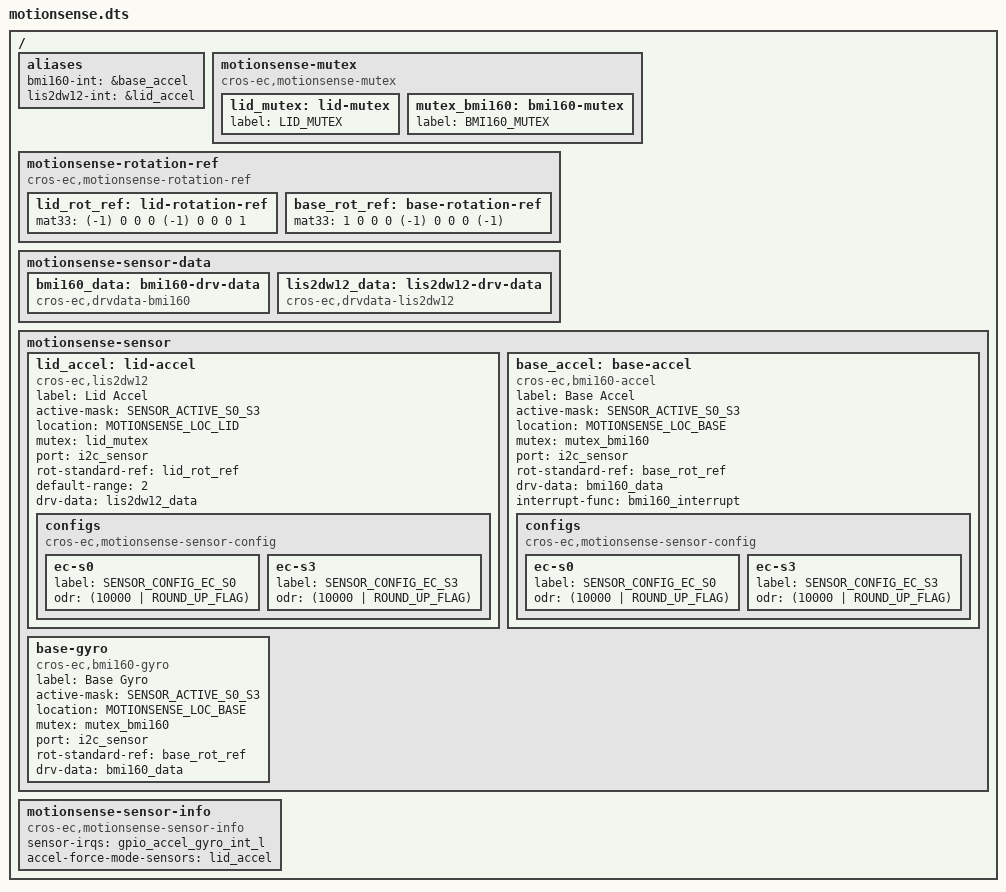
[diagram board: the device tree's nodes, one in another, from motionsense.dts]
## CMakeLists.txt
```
<<<<<<< HEAD   (caf383 driver: add ICM-42607 driver support)
=======
# Copyright 2021 The Chromium OS Authors. All rights reserved.
# Use of this source code is governed by a BSD-style license that can be
# found in the LICENSE file.

cmake_minimum_required(VERSION 3.13.1)
add_compile_definitions(BOARD_HAYATO)

find_package(Zephyr REQUIRED HINTS $ENV{ZEPHYR_BASE})
project(hayato)

zephyr_library_include_directories(include)

set(PLATFORM_EC_BASEBOARD "${PLATFORM_EC}/baseboard/asurada" CACHE PATH
    "Path to the platform/ec baseboard directory")
set(PLATFORM_EC_BOARD "${PLATFORM_EC}/board/hayato" CACHE PATH
  "Path to the platform/ec board directory")

zephyr_library_sources(
  "${PLATFORM_EC_BASEBOARD}/board_chipset.c"
  "${PLATFORM_EC_BASEBOARD}/board_id.c"
  "${PLATFORM_EC_BASEBOARD}/regulator.c"
  "${PLATFORM_EC_BASEBOARD}/usbc_config.c"
  "${PLATFORM_EC_BASEBOARD}/usb_pd_policy.c")

zephyr_library_sources(
  "${PLATFORM_EC_BOARD}/battery.c")

zephyr_library_sources_ifdef(CONFIG_PLATFORM_EC_I2C
  "src/i2c.c")
>>>>>>> CHANGE (2eb53a lid_angle: Create a common callback for lid angle changes)
```

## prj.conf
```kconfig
# Copyright 2021 The Chromium OS Authors. All rights reserved.
# Use of this source code is governed by a BSD-style license that can be
# found in the LICENSE file.

CONFIG_CROS_EC=y
CONFIG_PLATFORM_EC=y
CONFIG_SHIMMED_TASKS=y

# Bring up options
CONFIG_KERNEL_SHELL=y
CONFIG_PLATFORM_EC_SYSTEM_UNLOCKED=y

# Battery
CONFIG_PLATFORM_EC_BATTERY=y
CONFIG_PLATFORM_EC_BATTERY_CUT_OFF=y
CONFIG_PLATFORM_EC_BATTERY_FUEL_GAUGE=y
CONFIG_PLATFORM_EC_BATTERY_PRESENT_GPIO=y
CONFIG_PLATFORM_EC_BATTERY_SMART=y
CONFIG_PLATFORM_EC_BATT_FULL_CHIPSET_OFF_INPUT_LIMIT_MV=9000
CONFIG_PLATFORM_EC_I2C_PASSTHRU_RESTRICTED=y
CONFIG_PLATFORM_EC_I2C_VIRTUAL_BATTERY=y

# Charger
CONFIG_PLATFORM_EC_CHARGE_MANAGER=y
CONFIG_PLATFORM_EC_CHARGE_RAMP_HW=y
CONFIG_PLATFORM_EC_CHARGER_DISCHARGE_ON_AC=y
CONFIG_PLATFORM_EC_CHARGER_DISCHARGE_ON_AC_CHARGER=y
CONFIG_PLATFORM_EC_CHARGER_ISL9238C=y
CONFIG_PLATFORM_EC_CHARGER_MAINTAIN_VBAT=y
CONFIG_PLATFORM_EC_CHARGER_OTG=y
CONFIG_PLATFORM_EC_CHARGER_PSYS=y
CONFIG_PLATFORM_EC_CHARGER_PSYS_READ=y
# BOARD_RS2
CONFIG_PLATFORM_EC_CHARGER_SENSE_RESISTOR=10
# BOARD_RS1
CONFIG_PLATFORM_EC_CHARGER_SENSE_RESISTOR_AC=20

# Host Commands
CONFIG_PLATFORM_EC_HOSTCMD=y
CONFIG_PLATFORM_EC_CONSOLE_CMD_ACCELS=y
CONFIG_PLATFORM_EC_CONSOLE_CMD_ACCEL_INFO=y
CONFIG_PLATFORM_EC_CONSOLE_CMD_CHARGER_ADC_AMON_BMON=y
CONFIG_PLATFORM_EC_CONSOLE_CMD_SYSINFO=y
CONFIG_PLATFORM_EC_HOSTCMD_REGULATOR=y
CONFIG_PLATFORM_EC_HOST_COMMAND_STATUS=y

# LED
CONFIG_PLATFORM_EC_LED_COMMON=y
CONFIG_PLATFORM_EC_LED_ONOFF_STATES=y
CONFIG_PLATFORM_EC_LED_ONOFF_STATES_BAT_LOW=10

# MKBP event mask
CONFIG_PLATFORM_EC_MKBP_EVENT_WAKEUP_MASK=y
CONFIG_PLATFORM_EC_MKBP_HOST_EVENT_WAKEUP_MASK=y

# Sensors
CONFIG_PLATFORM_EC_MOTIONSENSE=y
CONFIG_PLATFORM_EC_ACCEL_FIFO=y
CONFIG_PLATFORM_EC_ACCEL_INTERRUPTS=y
CONFIG_PLATFORM_EC_GMR_TABLET_MODE=y
CONFIG_PLATFORM_EC_LID_ANGLE=y
CONFIG_PLATFORM_EC_LID_ANGLE_UPDATE=y
CONFIG_PLATFORM_EC_SENSOR_TIGHT_TIMESTAMPS=y
CONFIG_PLATFORM_EC_SWITCH=y
CONFIG_PLATFORM_EC_TABLET_MODE=y
CONFIG_PLATFORM_EC_TABLET_MODE_SWITCH=y

# Sensor Drivers
CONFIG_PLATFORM_EC_ACCEL_LIS2DW12=y
CONFIG_PLATFORM_EC_ACCEL_LIS2DW12_AS_BASE=y
CONFIG_PLATFORM_EC_ACCELGYRO_BMI160=y
CONFIG_PLATFORM_EC_ACCELGYRO_BMI_COMM_I2C=y

# USB-A
CONFIG_PLATFORM_EC_USB_A_PORT_COUNT=1

# USB-C
CONFIG_PLATFORM_EC_BC12_DETECT_PI3USB9201=y
CONFIG_PLATFORM_EC_BC12_DETECT_MT6360=y
CONFIG_PLATFORM_EC_BC12_SINGLE_DRIVER=n
CONFIG_PLATFORM_EC_MT6360_BC12_GPIO=y
CONFIG_PLATFORM_EC_SMBUS_PEC=y
CONFIG_PLATFORM_EC_USBC_PPC_DEDICATED_INT=y
CONFIG_PLATFORM_EC_USBC_PPC_SYV682C=y
CONFIG_PLATFORM_EC_USBC_PPC_SYV682X=y
CONFIG_PLATFORM_EC_USB_MUX_IT5205=y
CONFIG_PLATFORM_EC_USB_MUX_PS8743=y
CONFIG_PLATFORM_EC_USB_MUX_VIRTUAL=y
CONFIG_PLATFORM_EC_USB_PD_DISCHARGE_PPC=y
CONFIG_PLATFORM_EC_USB_PD_DP_HPD_GPIO=y
CONFIG_PLATFORM_EC_USB_PD_DP_HPD_GPIO_CUSTOM=y
CONFIG_PLATFORM_EC_USB_PD_FRS=y
CONFIG_PLATFORM_EC_USB_PD_FRS_PPC=y
CONFIG_PLATFORM_EC_USB_PD_ITE_ACTIVE_PORT_COUNT=2
CONFIG_PLATFORM_EC_USB_PD_LOGGING=y
CONFIG_PLATFORM_EC_USB_PD_TCPM_DRIVER_IT8XXX2=y
CONFIG_PLATFORM_EC_USB_PD_TCPC_RUNTIME_CONFIG=n
CONFIG_PLATFORM_EC_USB_MUX_RUNTIME_CONFIG=n
CONFIG_PLATFORM_EC_USB_PD_TCPM_ITE_ON_CHIP=y
CONFIG_PLATFORM_EC_USB_PD_TCPM_TCPCI=y
CONFIG_PLATFORM_EC_USB_PD_VBUS_DETECT_PPC=y
CONFIG_PLATFORM_EC_USB_PD_VBUS_MEASURE_ADC_EACH_PORT=y
CONFIG_PLATFORM_EC_USB_PORT_POWER_DUMB_CUSTOM_HOOK=y
CONFIG_PLATFORM_EC_USB_PD_DUAL_ROLE_AUTO_TOGGLE=n
CONFIG_PLATFORM_EC_USB_PD_USB32_DRD=n
CONFIG_PLATFORM_EC_USB_PD_USB4=n
CONFIG_PLATFORM_EC_USB_PD_TBT_COMPAT_MODE=n
CONFIG_PLATFORM_EC_USB_PD_PORT_COUNT_RUNTIME=y

# USB ID
# This is allocated for Asurada
# http://google3/hardware/standards/usb/
# TODO(b/183608112): Move to device tree
CONFIG_PLATFORM_EC_USB_PID=0x5053

# VBoot without EFS2
CONFIG_PLATFORM_EC_VBOOT_EFS2=n
CONFIG_PLATFORM_EC_VBOOT_HASH=y

# TODO(b/180980668): bring these features up
CONFIG_LTO=n
CONFIG_PLATFORM_EC_BACKLIGHT_LID=n
```

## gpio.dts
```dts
<<<<<<< HEAD   (8c53b8 battery: Set EC_BATT_FLAG_INVALID_DATA correctly)
=======
/* Copyright 2021 The Chromium OS Authors. All rights reserved.
 * Use of this source code is governed by a BSD-style license that can be
 * found in the LICENSE file.
 */

/ {
	named-gpios {
		compatible = "named-gpios";

		power_button_l: power_button_l {
			gpios = <&gpioe 4 GPIO_INPUT_PULL_UP>;
			enum-name = "GPIO_POWER_BUTTON_L";
		};
		lid_open: lid_open {
			gpios = <&gpioe 2 GPIO_INPUT>;
			enum-name = "GPIO_LID_OPEN";
		};
		tablet_mode_l {
			gpios = <&gpioj 7 GPIO_INPUT>;
			enum-name = "GPIO_TABLET_MODE_L";
		};
		ap_ec_warm_rst_req {
			gpios = <&gpiod 3 (GPIO_INPUT | GPIO_VOLTAGE_1P8)>;
			enum-name = "GPIO_AP_EC_WARM_RST_REQ";
		};
		ap_ec_watchdog_l: ap_ec_watchdog_l {
			gpios = <&gpioc 7 (GPIO_INPUT | GPIO_VOLTAGE_1P8 |
					GPIO_ACTIVE_LOW)>;
			enum-name = "GPIO_AP_EC_WATCHDOG_L";
		};
		ap_in_sleep_l: ap_in_sleep_l {
			gpios = <&gpiof 2 (GPIO_INPUT_PULL_DOWN |
					GPIO_VOLTAGE_1P8 | GPIO_ACTIVE_LOW)>;
			enum-name = "GPIO_AP_IN_SLEEP_L";
		};
		ap_xhci_init_done {
			gpios = <&gpiod 2 (GPIO_INPUT_PULL_DOWN |
					GPIO_VOLTAGE_1P8)>;
			enum-name = "GPIO_AP_XHCI_INIT_DONE";
		};
		pmic_ec_pwrgd: pmic_ec_pwrgd {
			gpios = <&gpiof 3 (GPIO_INPUT_PULL_DOWN |
					GPIO_VOLTAGE_1P8 | GPIO_ACTIVE_HIGH)>;
			enum-name = "GPIO_PMIC_EC_PWRGD";
		};
		gpio_accel_gyro_int_l: base_imu_int_l {
			gpios = <&gpioj 2 (GPIO_INPUT | GPIO_VOLTAGE_1P8)>;
			enum-name = "GPIO_EC_IMU_INT_L";
		};
		lid_accel_int_l {
			gpios = <&gpioj 3 (GPIO_INPUT | GPIO_VOLTAGE_1P8)>;
			enum-name = "GPIO_LID_ACCEL_INT_L";
		};
		als_rgb_int_odl {
			gpios = <&gpiof 0 GPIO_INPUT>;
			enum-name = "GPIO_ALS_RGB_INT_ODL";
		};
		usb_c0_ppc_int_odl {
			gpios = <&gpiod 1 GPIO_INPUT>;
			enum-name = "GPIO_USB_C0_PPC_INT_ODL";
		};
		usb_c0_bc12_int_odl {
			gpios = <&gpioj 6 GPIO_INPUT>;
			enum-name = "GPIO_USB_C0_BC12_INT_ODL";
		};
		usb_c1_bc12_int_l {
			gpios = <&gpioj 4 GPIO_INPUT>;
			enum-name = "GPIO_USB_C1_BC12_INT_L";
		};
		volume_down_l {
			gpios = <&gpiod 5 GPIO_INPUT_PULL_UP>;
			enum-name = "GPIO_VOLUME_DOWN_L";
		};
		volume_up_l {
			gpios = <&gpiod 6 GPIO_INPUT_PULL_UP>;
			enum-name = "GPIO_VOLUME_UP_L";
		};
		ac_present: ac_present {
			gpios = <&gpioe 5 GPIO_INPUT>;
			enum-name = "GPIO_AC_PRESENT";
		};
		wp {
			gpios = <&gpioi 4 (GPIO_INPUT | GPIO_VOLTAGE_1P8)>;
			enum-name = "GPIO_WP";
		};
		spi0_cs {
			gpios = <&gpiom 5 (GPIO_INPUT | GPIO_VOLTAGE_1P8)>;
			enum-name = "GPIO_SPI0_CS";
		};
		x_ec_gpio2 {
			gpios = <&gpiob 2 GPIO_ODR_HIGH>;
			enum-name = "GPIO_X_EC_GPIO2";
		};
		ec_pmic_en_odl {
			gpios = <&gpiod 0 (GPIO_ODR_HIGH | GPIO_VOLTAGE_1P8)>;
			enum-name = "GPIO_EC_PMIC_EN_ODL";
		};
		ec_pmic_watchdog_l {
			gpios = <&gpioh 0 (GPIO_ODR_LOW | GPIO_VOLTAGE_1P8)>;
			enum-name = "GPIO_EC_PMIC_WATCHDOG_L";
		};
		en_pp5000_a {
			gpios = <&gpioc 6 GPIO_OUT_HIGH>;
			enum-name = "GPIO_EN_PP5000_A";
		};
		pg_mt6315_proc_odl {
			gpios = <&gpioe 1 GPIO_INPUT>;
			enum-name = "GPIO_PG_MT6315_PROC_ODL";
		};
		pg_mt6360_odl {
			gpios = <&gpiof 1 GPIO_INPUT>;
			enum-name = "GPIO_PG_MT6360_ODL";
		};
		pg_pp5000_a_odl {
			gpios = <&gpioa 6 GPIO_INPUT>;
			enum-name = "GPIO_PG_PP5000_A_ODL";
		};
		en_slp_z {
			gpios = <&gpioe 3 GPIO_OUT_LOW>;
			enum-name = "GPIO_EN_SLP_Z";
		};
		sys_rst_odl {
			gpios = <&gpiob 6 GPIO_ODR_LOW>;
			enum-name = "GPIO_SYS_RST_ODL";
		};
		ec_bl_en_od {
			gpios = <&gpiob 5 (GPIO_ODR_LOW | GPIO_VOLTAGE_1P8)>;
			enum-name = "GPIO_EC_BL_EN_OD";
		};
		ec_int_l {
			gpios = <&gpioe 6 (GPIO_ODR_HIGH | GPIO_VOLTAGE_1P8)>;
			enum-name = "GPIO_EC_INT_L";
		};
		dp_aux_path_sel {
			gpios = <&gpiog 0 GPIO_OUT_HIGH>;
			enum-name = "GPIO_DP_AUX_PATH_SEL";
		};
		ec_dpbrdg_hpd_odl {
			gpios = <&gpioj 0 (GPIO_ODR_HIGH | GPIO_VOLTAGE_1P8)>;
			enum-name = "GPIO_EC_DPBRDG_HPD_ODL";
		};
		en_pp5000_usb_a0_vbus {
			gpios = <&gpiob 7 GPIO_OUT_LOW>;
			enum-name = "GPIO_EN_PP5000_USB_A0_VBUS";
		};
		usb_c0_frs_en {
			gpios = <&gpioh 3 GPIO_OUT_LOW>;
			enum-name = "GPIO_USB_C0_FRS_EN";
		};
		ec_batt_pres_odl {
			gpios = <&gpioc 0 GPIO_INPUT>;
			enum-name = "GPIO_BATT_PRES_ODL";
		};
		bc12_det_en {
			gpios = <&gpioj 5 GPIO_OUT_LOW>;
			enum-name = "GPIO_BC12_DET_EN";
		};
		en_ec_id_odl {
			gpios = <&gpioh 5 GPIO_ODR_LOW>;
			enum-name = "GPIO_EN_EC_ID_ODL";
		};
		entering_rw {
			gpios = <&gpioc 5 GPIO_OUT_LOW>;
			enum-name = "GPIO_ENTERING_RW";
		};
		en_5v_usm {
			gpios = <&gpiod 7 GPIO_OUT_LOW>;
			enum-name = "GPIO_EN_5V_USM";
		};
		i2c_b_scl {
			gpios = <&gpiob 3 GPIO_INPUT>;
			enum-name = "GPIO_I2C_B_SCL";
		};
		i2c_b_sda {
			gpios = <&gpiob 4 GPIO_INPUT>;
			enum-name = "GPIO_I2C_B_SDA";
		};
		i2c_c_scl {
			gpios = <&gpioc 1 (GPIO_INPUT | GPIO_VOLTAGE_1P8)>;
			enum-name = "GPIO_I2C_C_SCL";
		};
		i2c_c_sda {
			gpios = <&gpioc 2 (GPIO_INPUT | GPIO_VOLTAGE_1P8)>;
			enum-name = "GPIO_I2C_C_SDA";
		};
		i2c_e_scl {
			gpios = <&gpioe 0 GPIO_INPUT>;
			enum-name = "GPIO_I2C_E_SCL";
		};
		i2c_e_sda {
			gpios = <&gpioe 7 GPIO_INPUT>;
			enum-name = "GPIO_I2C_E_SDA";
		};
		i2c_f_scl {
			gpios = <&gpiof 6 GPIO_INPUT>;
			enum-name = "GPIO_I2C_F_SCL";
		};
		i2c_f_sda {
			gpios = <&gpiof 7 GPIO_INPUT>;
			enum-name = "GPIO_I2C_F_SDA";
		};
		ec_x_gpio1 {
			gpios = <&gpioh 4 GPIO_OUT_LOW>;
			enum-name = "GPIO_EC_X_GPIO1";
		};
		ec_x_gpio3 {
			gpios = <&gpioj 1 GPIO_INPUT>;
			enum-name = "GPIO_EC_X_GPIO3";
		};
		set_vmc_volt_at_1v8 {
			gpios = <&gpiod 4 (GPIO_INPUT_PULL_DOWN |
					GPIO_VOLTAGE_1P8)>;
			enum-name = "GPIO_SET_VMC_VOLT_AT_1V8";
		};
		en_pp3000_vmc_pmu {
			gpios = <&gpiod 2 (GPIO_INPUT_PULL_DOWN |
					GPIO_VOLTAGE_1P8)>;
			enum-name = "GPIO_EN_PP3000_VMC_PMU";
		};
		packet_mode_en {
			gpios = <&gpioa 3 GPIO_INPUT_PULL_DOWN>;
			enum-name = "GPIO_PACKET_MODE_EN";
		};
		usb_a0_fault_odl {
			gpios = <&gpioa 7 GPIO_INPUT>;
			enum-name = "GPIO_USB_A0_FAULT_ODL";
		};
		charger_prochot_odl {
			gpios = <&gpioc 3 GPIO_INPUT>;
			enum-name = "GPIO_CHARGER_PROCHOT_ODL";
		};
		pg_mt6315_gpu_odl {
			gpios = <&gpioh 6 GPIO_INPUT>;
			enum-name = "GPIO_PG_MT6315_GPU_ODL";
		};
		en_pp3000_sd_u {
			gpios = <&gpiog 1 (GPIO_INPUT_PULL_DOWN |
					GPIO_VOLTAGE_1P8)>;
			enum-name = "GPIO_EN_PP3000_SD_U";
		};
		ccd_mode_odl {
			gpios = <&gpioc 4 GPIO_INPUT>;
			enum-name = "GPIO_CCD_MODE_ODL";
		};
		spi_clk_gpg6 {
			gpios = <&gpiog 6 GPIO_INPUT_PULL_UP>;
			enum-name = "GPIO_SPI_CLK_GPG6";
		};
		spi_mosi_gpg4 {
			gpios = <&gpiog 4 GPIO_OUT_LOW>;
			enum-name = "GPIO_SPI_MOSI_GPG4";
		};
		spi_miso_gpg5 {
			gpios = <&gpiog 5 GPIO_OUT_LOW>;
			enum-name = "GPIO_SPI_MISO_GPG5";
		};
		spi_cs_gpg7 {
			gpios = <&gpiog 7 GPIO_OUT_LOW>;
			enum-name = "GPIO_SPI_CS_GPG7";
		};
	};

	hibernate-wake-pins {
		compatible = "cros-ec,hibernate-wake-pins";
		wakeup-pins = <&ac_present
			       &power_button_l
			       &lid_open>;
	};

	power_signal_list: power-signal-list {
		compatible = "mt8192,power-signal-list";
		pmic_pwr_good {
			power-enum-name = "PMIC_PWR_GOOD";
			power-gpio-pin = <&pmic_ec_pwrgd>;
		};
		ap_in_s3_l {
			power-enum-name = "AP_IN_S3_L";
			power-gpio-pin = <&ap_in_sleep_l>;
		};
		ap_wdt_asserted {
			power-enum-name = "AP_WDT_ASSERTED";
			power-gpio-pin = <&ap_ec_watchdog_l>;
		};
	};

	unused-pins {
		compatible = "unused-gpios";

		unused-gpios =
			/* nc_gpg3 */
			<&gpiog 3 GPIO_OUT_LOW>,
			/* nc_gpi7 */
			<&gpioi 7 GPIO_OUT_LOW>,
			/* nc_gpm2 */
			<&gpiom 2 GPIO_INPUT_PULL_DOWN>,
			/* nc_gpm3 */
			<&gpiom 3 GPIO_INPUT_PULL_DOWN>,
			/* nc_gpm6 */
			<&gpiom 6 GPIO_INPUT_PULL_DOWN>;
	};
};
>>>>>>> CHANGE (eb25e8 Merge remote-tracking branch cros/main into firmware-dedede-)
```

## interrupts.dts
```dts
/* Copyright 2022 The Chromium OS Authors. All rights reserved.
 * Use of this source code is governed by a BSD-style license that can be
 * found in the LICENSE file.
 */

/ {
	gpio-interrupts {
		compatible = "cros-ec,gpio-interrupts";

		int_power_button: power_button {
			gpio = <&power_button_l>;
			flags = <GPIO_INT_EDGE_BOTH>;
			handler = "power_button_interrupt";
		};
		int_lid_open: lid_open {
			gpio = <&lid_open>;
			flags = <GPIO_INT_EDGE_BOTH>;
			handler = "lid_interrupt";
		};
		int_base_imu_int_l: base_imu_int_l {
			gpio = <&gpio_accel_gyro_int_l>;
			flags = <GPIO_INT_EDGE_FALLING>;
			handler = "bmi160_interrupt";
		};
		int_lid_accel_int_l: lid_accel_int_l {
			gpio = <&gpio_lid_accel_int_l>;
			flags = <GPIO_INT_EDGE_FALLING>;
			handler = "lis2dw12_interrupt";
		};
		int_tablet_mode_l: tablet_mode_l {
			gpio = <&gpio_tablet_mode_l>;
			flags = <GPIO_INT_EDGE_BOTH>;
			handler = "gmr_tablet_switch_isr";
		};
		int_usb_c0_ppc_int_odl: usb_c0_ppc_int_odl {
			gpio = <&gpio_usb_c0_ppc_int_odl>;
			flags = <GPIO_INT_EDGE_BOTH>;
			handler = "ppc_interrupt";
		};
		int_usb_c0_bc12_int_odl: usb_c0_bc12_int_odl {
			gpio = <&gpio_usb_c0_bc12_int_odl>;
			flags = <GPIO_INT_EDGE_FALLING>;
			handler = "bc12_interrupt";
		};
		int_usb_c1_bc12_int_l: usb_c1_bc12_int_l {
			gpio = <&gpio_usb_c1_bc12_int_l>;
			flags = <GPIO_INT_EDGE_FALLING>;
			handler = "bc12_interrupt";
		};
		int_ac_present: ac_present {
			gpio = <&ac_present>;
			flags = <GPIO_INT_EDGE_BOTH>;
			handler = "extpower_interrupt";
		};
		int_x_ec_gpio2: x_ec_gpio2 {
			gpio = <&gpio_x_ec_gpio2>;
			flags = <GPIO_INT_EDGE_FALLING>;
			handler = "x_ec_interrupt";
		};
		int_ap_xhci_init_done: ap_xhci_init_done {
			gpio = <&gpio_ap_xhci_init_done>;
			flags = <GPIO_INT_EDGE_BOTH>;
			handler = "usb_a0_interrupt";
		};
		int_ap_ec_watchdog_l: ap_ec_watchdog_l {
			gpio = <&ap_ec_watchdog_l>;
			flags = <GPIO_INT_EDGE_BOTH>;
			handler = "chipset_watchdog_interrupt";
		};
		int_ap_in_sleep_l: ap_in_sleep_l {
			gpio = <&ap_in_sleep_l>;
			flags = <GPIO_INT_EDGE_BOTH>;
			handler = "power_signal_interrupt";
		};
		int_pmic_ec_pwrgd: pmic_ec_pwrgd {
			gpio = <&pmic_ec_pwrgd>;
			flags = <GPIO_INT_EDGE_BOTH>;
			handler = "power_signal_interrupt";
		};
		int_ap_ec_warm_rst_req: ap_ec_warm_rst_req {
			gpio = <&gpio_ap_ec_warm_rst_req>;
			flags = <GPIO_INT_EDGE_BOTH>;
			handler = "chipset_reset_request_interrupt";
		};
		int_ap_in_sleep_l: ap_in_sleep_l {
			gpio = <&ap_in_sleep_l>;
			flags = <GPIO_INT_EDGE_BOTH>;
			handler = "power_signal_interrupt";
		};
		int_spi0_cs: spi0_cs {
			gpio = <&gpio_spi0_cs>;
			flags = <GPIO_INT_EDGE_FALLING>;
			handler = "spi_event";
		};
	};
};
```

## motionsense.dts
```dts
/* Copyright 2020 The Chromium OS Authors. All rights reserved.
 * Use of this source code is governed by a BSD-style license that can be
 * found in the LICENSE file.
 */

#include <dt-bindings/motionsense/utils.h>


/ {
	aliases {
		/*
		 * motion sense's <>_INT_EVENT is handled
		 * by alias. Using the alias, each driver creates
		 * its own <>_INT_EVENT.
		 */
		bmi160-int = &base_accel;
		lis2dw12-int = &lid_accel;
	};

	/*
	 * Declare mutexes used by sensor drivers.
	 * A mutex node is used to create an instance of mutex_t.
	 * A mutex node is referenced by a sensor node if the
	 * corresponding sensor driver needs to use the
	 * instance of the mutex.
	 */
	motionsense-mutex {
		compatible = "cros-ec,motionsense-mutex";
		lid_mutex: lid-mutex {
			label = "LID_MUTEX";
		};

		mutex_bmi160: bmi160-mutex {
			label = "BMI160_MUTEX";
		};
	};

	/* Rotation matrix used by drivers. */
	motionsense-rotation-ref {
		compatible = "cros-ec,motionsense-rotation-ref";
		lid_rot_ref: lid-rotation-ref {
			mat33 = <(-1) 0 0
				 0 (-1) 0
				 0 0 1>;
		};

		base_rot_ref: base-rotation-ref {
			mat33 = <1 0 0
				 0 (-1) 0
				 0 0 (-1)>;
		};
	};

	/*
	 * Driver specific data. A driver-specific data can be shared with
	 * different motion sensors while they are using the same driver.
	 *
	 * If a node's compatible starts with "cros-ec,accelgyro-", it is for
	 * a common structure defined in accelgyro.h.
	 * e.g) compatible = "cros-ec,accelgyro-als-drv-data" is for
	 * "struct als_drv_data_t" in accelgyro.h
	 */
	motionsense-sensor-data {
		bmi160_data: bmi160-drv-data {
			compatible = "cros-ec,drvdata-bmi160";
			status = "okay";
		};

		lis2dw12_data: lis2dw12-drv-data {
			compatible = "cros-ec,drvdata-lis2dw12";
			status = "okay";
		};
	};

	/*
	 * List of motion sensors that creates motion_sensors array.
	 * The label "lid_accel" and "base_accel" are used to indicate
	 * motion sensor IDs for lid angle calculation.
	 */
	motionsense-sensor {
		lid_accel: lid-accel {
			compatible = "cros-ec,lis2dw12";
			status = "okay";

			label = "Lid Accel";
			active-mask = "SENSOR_ACTIVE_S0_S3";
			location = "MOTIONSENSE_LOC_LID";
			mutex = <&lid_mutex>;
			port = <&i2c_sensor>;
			rot-standard-ref = <&lid_rot_ref>;
			default-range = <2>;
			drv-data = <&lis2dw12_data>;
			configs {
				compatible =
					"cros-ec,motionsense-sensor-config";
				ec-s0 {
					label = "SENSOR_CONFIG_EC_S0";
					odr = <(10000 | ROUND_UP_FLAG)>;
				};
				ec-s3 {
					label = "SENSOR_CONFIG_EC_S3";
					odr = <(10000 | ROUND_UP_FLAG)>;
				};
			};
		};

		base_accel: base-accel {
			compatible = "cros-ec,bmi160-accel";
			status = "okay";

			label = "Base Accel";
			active-mask = "SENSOR_ACTIVE_S0_S3";
			location = "MOTIONSENSE_LOC_BASE";
			mutex = <&mutex_bmi160>;
			port = <&i2c_sensor>;
			rot-standard-ref = <&base_rot_ref>;
			drv-data = <&bmi160_data>;
			interrupt-func = "bmi160_interrupt";
			configs {
				compatible =
					"cros-ec,motionsense-sensor-config";
				ec-s0 {
					label = "SENSOR_CONFIG_EC_S0";
					odr = <(10000 | ROUND_UP_FLAG)>;
				};
				ec-s3 {
					label = "SENSOR_CONFIG_EC_S3";
					odr = <(10000 | ROUND_UP_FLAG)>;
				};
			};
		};

		base-gyro {
			compatible = "cros-ec,bmi160-gyro";
			status = "okay";

			label = "Base Gyro";
			active-mask = "SENSOR_ACTIVE_S0_S3";
			location = "MOTIONSENSE_LOC_BASE";
			mutex = <&mutex_bmi160>;
			port = <&i2c_sensor>;
			rot-standard-ref = <&base_rot_ref>;
			drv-data = <&bmi160_data>;
		};
	};

	motionsense-sensor-info {
		compatible = "cros-ec,motionsense-sensor-info";

		/*
		 * list of GPIO interrupts that have to
		 * be enabled at initial stage
		 */
		sensor-irqs = <&gpio_accel_gyro_int_l>;
		/* list of sensors in force mode */
		accel-force-mode-sensors = <&lid_accel>;
	};
};
```

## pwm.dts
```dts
/* Copyright 2021 The Chromium OS Authors. All rights reserved.
 * Use of this source code is governed by a BSD-style license that can be
 * found in the LICENSE file.
 */

/ {
	named-pwms {
		compatible = "named-pwms";
		/* NOTE: &pwm number needs same with channel number */
		led1: led1 {
                        #pwm-cells = <0>; /* for build. shim/src/pwm get cell. */
			pwms = <&pwm0 PWM_CHANNEL_0 PWM_POLARITY_INVERTED>;
			label = "LED1";
			/*
			 * If we need pwm output in ITE chip power saving
			 * mode, then we should set frequency <=324Hz.
			 */
			frequency = <324>;
		};
		led2: led2 {
                        #pwm-cells = <0>;
			pwms = <&pwm1 PWM_CHANNEL_1 PWM_POLARITY_INVERTED>;
			label = "LED2";
			frequency = <324>;
		};
		led3: led3 {
                        #pwm-cells = <0>;
			pwms = <&pwm2 PWM_CHANNEL_2 PWM_POLARITY_INVERTED>;
			label = "LED3";
			frequency = <324>;
		};
	};
};

/* LED1 */
&pwm0 {
	status = "okay";
	prescaler-cx = <PWM_PRESCALER_C4>;
};

/* LED2 */
&pwm1 {
	status = "okay";
	prescaler-cx = <PWM_PRESCALER_C4>;
};

/* LED3 */
&pwm2 {
	status = "okay";
	prescaler-cx = <PWM_PRESCALER_C4>;
};
```

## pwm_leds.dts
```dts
/* Copyright 2021 The Chromium OS Authors. All rights reserved.
 * Use of this source code is governed by a BSD-style license that can be
 * found in the LICENSE file.
 */

/ {
	pwmleds {
		compatible = "pwm-leds";
		pwm_led0: pwm_led_0 {
			pwms = <&led1
				&led2
				&led3>; /* same color-map color order */
		};
	};

	cros-pwmleds {
		compatible = "cros-ec,pwm-leds";

		leds = <&pwm_led0>;

		color-map-red    = <100   0   0>;
		color-map-green  = <  0 100   0>;
		color-map-blue   = <  0   0 100>;
		color-map-yellow = <100  70   0>;
		color-map-white  = <100  70 100>;
		color-map-amber  = <100  20   0>; /* hayato needn't these map */

		brightness-range = <0 0 0 0 15 15>; /* via led_get_brightness_range(), then need't */
	};
};
```

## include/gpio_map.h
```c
/* Copyright 2021 The Chromium OS Authors. All rights reserved.
 * Use of this source code is governed by a BSD-style license that can be
 * found in the LICENSE file.
 */

#ifndef __ZEPHYR_GPIO_MAP_H
#define __ZEPHYR_GPIO_MAP_H

#define GPIO_ENTERING_RW		GPIO_UNIMPLEMENTED
#define GPIO_WP_L			GPIO_UNIMPLEMENTED

#ifdef CONFIG_PLATFORM_EC_GMR_TABLET_MODE
#define GMR_TABLET_MODE_GPIO_L GPIO_TABLET_MODE_L
#endif

#define GPIO_EN_PP5000 GPIO_EN_PP5000_A

#endif /* __ZEPHYR_GPIO_MAP_H */
```

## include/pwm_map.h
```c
/* Copyright 2021 The Chromium OS Authors. All rights reserved.
 * Use of this source code is governed by a BSD-style license that can be
 * found in the LICENSE file.
 */

#ifndef __ZEPHYR_CHROME_PWM_MAP_H
#define __ZEPHYR_CHROME_PWM_MAP_H

#include <devicetree.h>

#include "config.h"

#include "pwm/pwm.h"

/*
 * TODO(b/177452529): eliminate the dependency on enum pwm_channel
 * and configure this information directly from the device tree.
 */
#define PWM_CH_LED1	NAMED_PWM(led1) // delete? get from dts
#define PWM_CH_LED2	NAMED_PWM(led2)
#define PWM_CH_LED3	NAMED_PWM(led3)

#endif /* __ZEPHYR_CHROME_PWM_MAP_H */
```

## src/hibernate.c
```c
/* Copyright 2021 The Chromium OS Authors. All rights reserved.
 * Use of this source code is governed by a BSD-style license that can be
 * found in the LICENSE file.
 */

#include "charger.h"
#include "driver/charger/isl923x_public.h"
#include "gpio.h"
#include "system.h"

/* Hayato board specific hibernate implementation */
__override void board_hibernate_late(void)
{
	/*
	 * Turn off PP5000_A. Required for devices without Z-state.
	 * Don't care for devices with Z-state.
	 */
	gpio_set_level(GPIO_EN_PP5000_A, 0);

	/*
	 * GPIO_EN_SLP_Z not implemented in rev0/1,
	 * fallback to usual hibernate process.
	 */
	if (board_get_version() <= 1)
		return;

	isl9238c_hibernate(CHARGER_SOLO);

	gpio_set_level(GPIO_EN_SLP_Z, 1);

	/* should not reach here */
	__builtin_unreachable();
}
```
